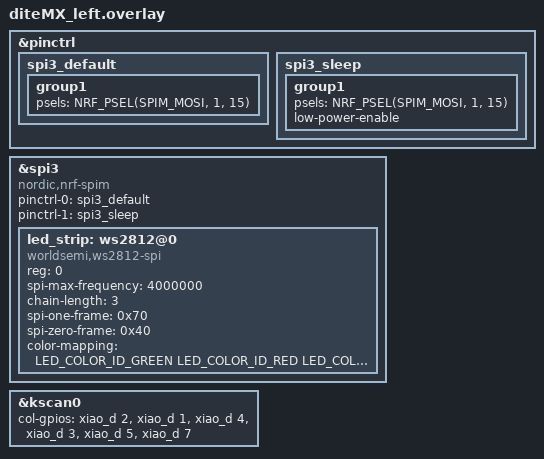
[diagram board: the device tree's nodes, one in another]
// diteMX_left.overlay

#include "diteMX.dtsi" // Notice that the main dtsi files are included in the overlay.
#include <dt-bindings/led/led.h>

&pinctrl {
    spi3_default: spi3_default {
        group1 {
            psels = <NRF_PSEL(SPIM_MOSI, 1, 15)>;
        };
    };

    spi3_sleep: spi3_sleep {
        group1 {
            psels = <NRF_PSEL(SPIM_MOSI, 1, 15)>;
            low-power-enable;
        };
    };
};

&spi3 {
    compatible = "nordic,nrf-spim";
    status = "okay";

    pinctrl-0 = <&spi3_default>;
    pinctrl-1 = <&spi3_sleep>;
    pinctrl-names = "default", "sleep";

    led_strip: ws2812@0 {
        compatible = "worldsemi,ws2812-spi";

        /* SPI */
        reg = <0>; /* ignored, but necessary for SPI bindings */
        spi-max-frequency = <4000000>;

        /* WS2812 */
        chain-length = <3>; /* number of LEDs */
        spi-one-frame = <0x70>;
        spi-zero-frame = <0x40>;
        color-mapping = <LED_COLOR_ID_GREEN
                         LED_COLOR_ID_RED
                         LED_COLOR_ID_BLUE>;
    };
};

&kscan0 {
    col-gpios
        = <&xiao_d 2 GPIO_ACTIVE_HIGH> 
        , <&xiao_d 1 GPIO_ACTIVE_HIGH> 
        , <&xiao_d 4 GPIO_ACTIVE_HIGH> 
        , <&xiao_d 3 GPIO_ACTIVE_HIGH> 
        , <&xiao_d 5 GPIO_ACTIVE_HIGH> 
        , <&xiao_d 7 GPIO_ACTIVE_HIGH> 
        ;
};

// 0- 14     5v  -13
// 1- 13     GND -12
// 2- 12     3v3 -11
// 3- 11     4   -10
// 4- 10     5   -9
// 5- 9      6   -8
// 6- 8      7   -7

